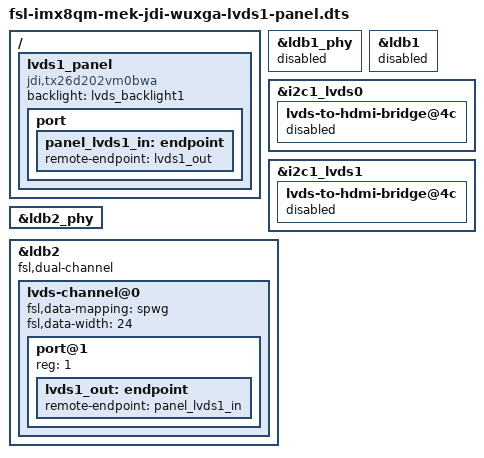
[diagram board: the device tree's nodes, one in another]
/*
 * Copyright 2017 NXP
 *
 * This program is free software; you can redistribute it and/or
 * modify it under the terms of the GNU General Public License
 * as published by the Free Software Foundation; either version 2
 * of the License, or (at your option) any later version.
 *
 * This program is distributed in the hope that it will be useful,
 * but WITHOUT ANY WARRANTY; without even the implied warranty of
 * MERCHANTABILITY or FITNESS FOR A PARTICULAR PURPOSE.  See the
 * GNU General Public License for more details.
 */

#include "fsl-imx8qm-mek.dts"

/ {
	lvds1_panel {
		compatible = "jdi,tx26d202vm0bwa";
		backlight = <&lvds_backlight1>;

		port {
			panel_lvds1_in: endpoint {
				remote-endpoint = <&lvds1_out>;
			};
		};
	};
};

&ldb1_phy {
	status = "disabled";
};

&ldb1 {
	status = "disabled";
};

&i2c1_lvds0 {
	lvds-to-hdmi-bridge@4c {
		status = "disabled";
	};
};

&i2c1_lvds1 {
	lvds-to-hdmi-bridge@4c {
	status = "disabled";
	};
};

&ldb2_phy {
	status = "okay";
};

&ldb2 {
	status = "okay";
	fsl,dual-channel;

	lvds-channel@0 {
		fsl,data-mapping = "spwg";
		fsl,data-width = <24>;
		status = "okay";

		port@1 {
			reg = <1>;

			lvds1_out: endpoint {
				remote-endpoint = <&panel_lvds1_in>;
			};
		};
	};
};
